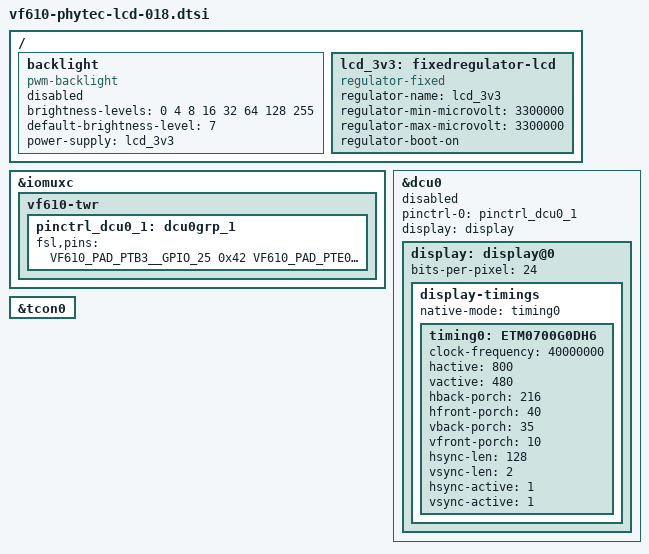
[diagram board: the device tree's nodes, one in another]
/*
 * Copyright (C) 2015 Anna Horstmann <ahorstmann@phytec.com> PHYTEC
 *
 * This program is free software; you can redistribute it and/or modify
 * it under the terms of the GNU General Public License version 2 as
 * published by the Free Software Foundation.
 */

&iomuxc {
        vf610-twr {
		pinctrl_dcu0_1: dcu0grp_1 { 
			fsl,pins = <
				VF610_PAD_PTB3__GPIO_25		0x42
				VF610_PAD_PTE0__DCU0_HSYNC      0x42
				VF610_PAD_PTE1__DCU0_VSYNC      0x42
				VF610_PAD_PTE2__DCU0_PCLK       0x42
				VF610_PAD_PTE4__DCU0_DE         0x42
				VF610_PAD_PTE5__DCU0_R0         0x42
				VF610_PAD_PTE6__DCU0_R1         0x42
				VF610_PAD_PTE7__DCU0_R2         0x42
				VF610_PAD_PTE8__DCU0_R3         0x42
				VF610_PAD_PTE9__DCU0_R4         0x42
				VF610_PAD_PTE10__DCU0_R5        0x42
				VF610_PAD_PTE11__DCU0_R6        0x42
				VF610_PAD_PTE12__DCU0_R7        0x42
				VF610_PAD_PTE13__DCU0_G0        0x42
				VF610_PAD_PTE14__DCU0_G1        0x42
				VF610_PAD_PTE15__DCU0_G2        0x42
				VF610_PAD_PTE16__DCU0_G3        0x42
				VF610_PAD_PTE17__DCU0_G4        0x42
				VF610_PAD_PTE18__DCU0_G5        0x42
				VF610_PAD_PTE19__DCU0_G6        0x42
				VF610_PAD_PTE20__DCU0_G7        0x42
				VF610_PAD_PTE21__DCU0_B0        0x42
				VF610_PAD_PTE22__DCU0_B1        0x42
				VF610_PAD_PTE23__DCU0_B2        0x42
				VF610_PAD_PTE24__DCU0_B3        0x42
				VF610_PAD_PTE25__DCU0_B4        0x42
				VF610_PAD_PTE26__DCU0_B5        0x42
				VF610_PAD_PTE27__DCU0_B6        0x42
				VF610_PAD_PTE28__DCU0_B7        0x42
			>;
		};
	};
};

/ {
        backlight: backlight {
                compatible = "pwm-backlight";
                brightness-levels = <0 4 8 16 32 64 128 255>;
                default-brightness-level = <7>;
                power-supply = <&lcd_3v3>;
                status = "disabled";
        };

        lcd_3v3: fixedregulator-lcd {
                compatible = "regulator-fixed";
                regulator-name = "lcd_3v3";
                regulator-min-microvolt = <3300000>;
                regulator-max-microvolt = <3300000>;
                regulator-boot-on;
        };

};

&dcu0 {
        pinctrl-names = "default";
        pinctrl-0 = <&pinctrl_dcu0_1>;
        display = <&display>;
/*	interrupts = <0 25 0x8>;*/	/*Error setting interrupt to active low: "					    genirq: Setting trigger mode 8 for irq 
					  57 failed (gic_set_type+0x0/0xe0)" */

					/* enable signal: pcm-952 gpio25
					   active low. vf610.dtsi sets 
					   interrupt as gpio30 */
        status = "disabled";
	display: display@0 {
                bits-per-pixel = <24>;

                display-timings {
                        native-mode = <&timing0>;
                        timing0: ETM0700G0DH6 {
                                clock-frequency = <40000000>;
                                hactive = <800>;
                                vactive = <480>;
                                hback-porch = <216>;
                                hfront-porch = <40>;
                                vback-porch = <35>;
                                vfront-porch = <10>;
                                hsync-len = <128>;
                                vsync-len = <2>;
                                hsync-active = <1>;
                                vsync-active = <1>;
                        };
                };
        };
};

&tcon0 {
        status = "okay";
};

